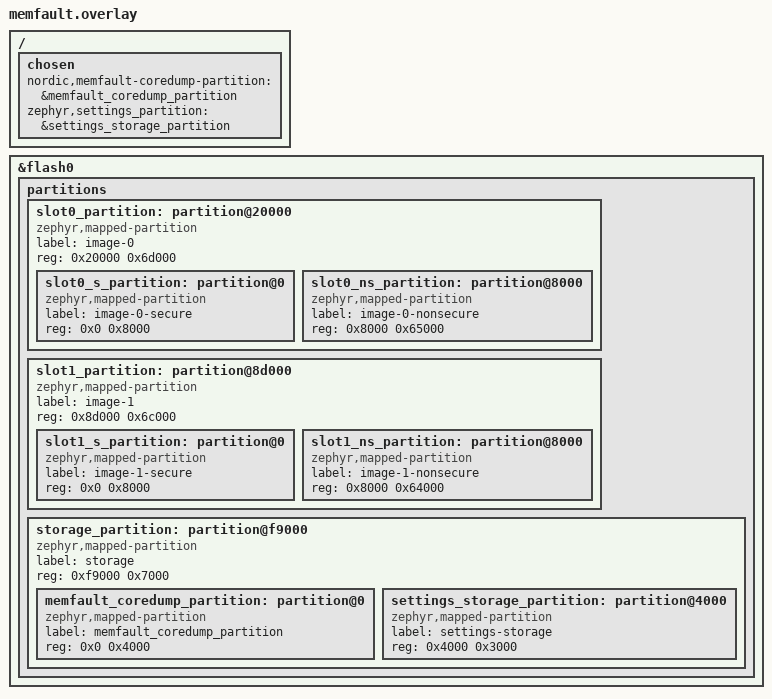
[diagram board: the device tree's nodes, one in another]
/*
 * Copyright (c) 2026 Nordic Semiconductor ASA
 *
 * SPDX-License-Identifier: LicenseRef-Nordic-5-Clause
 *
 * Flash partition overlay for nRF9151DK with Memfault core dump partition.
 */

/ {
	chosen {
		nordic,memfault-coredump-partition = &memfault_coredump_partition;
		zephyr,settings_partition = &settings_storage_partition;
	};
};

/delete-node/ &slot0_partition;
/delete-node/ &slot1_partition;
/delete-node/ &storage_partition;

&flash0 {
	partitions {
		ranges;
		#address-cells = <1>;
		#size-cells = <1>;

		slot0_partition: partition@20000 {
			compatible = "zephyr,mapped-partition";
			label = "image-0";
			reg = <0x20000 0x6d000>;
			ranges = <0x0 0x20000 0x6d000>;
			#address-cells = <1>;
			#size-cells = <1>;

			slot0_s_partition: partition@0 {
				compatible = "zephyr,mapped-partition";
				label = "image-0-secure";
				reg = <0x0 0x8000>;
			};

			slot0_ns_partition: partition@8000 {
				compatible = "zephyr,mapped-partition";
				label = "image-0-nonsecure";
				reg = <0x8000 0x65000>;
			};
		};

		slot1_partition: partition@8d000 {
			compatible = "zephyr,mapped-partition";
			label = "image-1";
			reg = <0x8d000 0x6c000>;
			ranges = <0x0 0x8d000 0x6c000>;
			#address-cells = <1>;
			#size-cells = <1>;

			slot1_s_partition: partition@0 {
				compatible = "zephyr,mapped-partition";
				label = "image-1-secure";
				reg = <0x0 0x8000>;
			};

			slot1_ns_partition: partition@8000 {
				compatible = "zephyr,mapped-partition";
				label = "image-1-nonsecure";
				reg = <0x8000 0x64000>;
			};
		};

		storage_partition: partition@f9000 {
			compatible = "zephyr,mapped-partition";
			label = "storage";
			reg = <0xf9000 0x7000>;
			ranges = <0x0 0xf9000 0x7000>;
			#address-cells = <1>;
			#size-cells = <1>;

			memfault_coredump_partition: partition@0 {
				compatible = "zephyr,mapped-partition";
				label = "memfault_coredump_partition";
				reg = <0x0 0x4000>;
			};

			settings_storage_partition: partition@4000 {
				compatible = "zephyr,mapped-partition";
				label = "settings-storage";
				reg = <0x4000 0x3000>;
			};
		};
	};
};
